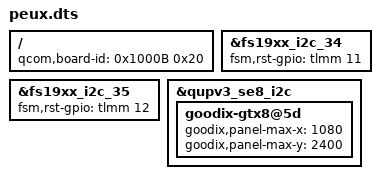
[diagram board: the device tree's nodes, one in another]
#include "veux.dts"

/ {
	qcom,board-id = <0x1000B 0x20>;
};

&fs19xx_i2c_34 {
		fsm,rst-gpio = <&tlmm 11 GPIO_ACTIVE_HIGH>;
};

&fs19xx_i2c_35 {
		fsm,rst-gpio = <&tlmm 12 GPIO_ACTIVE_HIGH>;
};

&qupv3_se8_i2c {
	goodix-gtx8@5d {
		goodix,panel-max-x = <1080>;
		goodix,panel-max-y = <2400>;
	};
};
